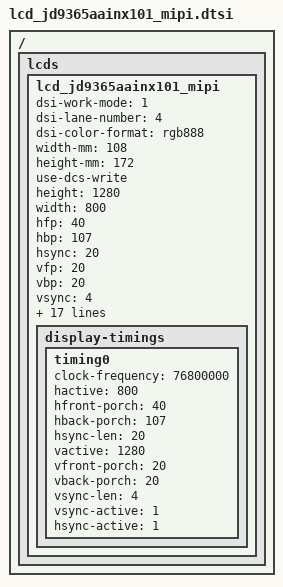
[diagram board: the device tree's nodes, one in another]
// SPDX-License-Identifier: GPL-2.0

/ { lcds: lcds {
        lcd_jd9365aainx101_mipi: lcd_jd9365aainx101_mipi {
                dsi-work-mode = <1>; /* video burst mode*/
                dsi-lane-number = <4>;
                dsi-color-format = "rgb888";
                width-mm = <108>;
                height-mm = <172>;
                use-dcs-write;

                /*mipi info*/
                height = <1280>;
                width = <800>;
                hfp = <40>;
                hbp = <107>;
                hsync = <20>;
                vfp = <20>;
                vbp = <20>;
                vsync = <4>;
                fps = <60>;
                work-mode = <0>;
                rgb-mode = <3>;
                lane-number = <4>;
                phy-bit-clock = <500000000>;
                split-enable = <0>;
                eotp-enable = <0>;
                burst-mode = <2>;
                esd-check-enable = <1>;

                /* DSI_CMD, DSI_MODE, timeout, len, cmd */
                initial-command = [
                        39 01 00 02 E0 00
                        39 01 00 02 E1 93
                        39 01 00 02 E2 65
                        39 01 00 02 E3 F8
                        39 01 00 02 80 03
                        39 01 00 02 E0 01
                        39 01 00 02 00 00
                        39 01 00 02 01 3B
                        39 01 00 02 0C 74
                        39 01 00 02 17 00
                        39 01 00 02 18 AF
                        39 01 00 02 19 00
                        39 01 00 02 1A 00
                        39 01 00 02 1B AF
                        39 01 00 02 1C 00
                        39 01 00 02 35 26
                        39 01 00 02 37 09
                        39 01 00 02 38 04
                        39 01 00 02 39 00
                        39 01 00 02 3A 01
                        39 01 00 02 3C 78
                        39 01 00 02 3D FF
                        39 01 00 02 3E FF
                        39 01 00 02 3F 7F
                        39 01 00 02 40 06
                        39 01 00 02 41 A0
                        39 01 00 02 42 81
                        39 01 00 02 43 14
                        39 01 00 02 44 23
                        39 01 00 02 45 28
                        39 01 00 02 55 02
                        39 01 00 02 57 69
                        39 01 00 02 59 0A
                        39 01 00 02 5A 2A
                        39 01 00 02 5B 17
                        39 01 00 02 5D 7F
                        39 01 00 02 5E 69
                        39 01 00 02 5F 59
                        39 01 00 02 60 4C
                        39 01 00 02 61 47
                        39 01 00 02 62 39
                        39 01 00 02 63 3B
                        39 01 00 02 64 24
                        39 01 00 02 65 3D
                        39 01 00 02 66 3C
                        39 01 00 02 67 3C
                        39 01 00 02 68 5A
                        39 01 00 02 69 46
                        39 01 00 02 6A 4A
                        39 01 00 02 6B 43
                        39 01 00 02 6C 46
                        39 01 00 02 6D 20
                        39 01 00 02 6E 0F
                        39 01 00 02 6F 00
                        39 01 00 02 70 7F
                        39 01 00 02 71 69
                        39 01 00 02 72 59
                        39 01 00 02 73 4C
                        39 01 00 02 74 47
                        39 01 00 02 75 39
                        39 01 00 02 76 3B
                        39 01 00 02 77 24
                        39 01 00 02 78 3D
                        39 01 00 02 79 3C
                        39 01 00 02 7A 3C
                        39 01 00 02 7B 5A
                        39 01 00 02 7C 46
                        39 01 00 02 7D 4A
                        39 01 00 02 7E 43
                        39 01 00 02 7F 46
                        39 01 00 02 80 20
                        39 01 00 02 81 0F
                        39 01 00 02 82 00
                        39 01 00 02 E0 02
                        39 01 00 02 00 42
                        39 01 00 02 01 42
                        39 01 00 02 02 40
                        39 01 00 02 03 40
                        39 01 00 02 04 5E
                        39 01 00 02 05 5E
                        39 01 00 02 06 5F
                        39 01 00 02 07 5F
                        39 01 00 02 08 5F
                        39 01 00 02 09 57
                        39 01 00 02 0A 57
                        39 01 00 02 0B 77
                        39 01 00 02 0C 77
                        39 01 00 02 0D 47
                        39 01 00 02 0E 47
                        39 01 00 02 0F 45
                        39 01 00 02 10 45
                        39 01 00 02 11 4B
                        39 01 00 02 12 4B
                        39 01 00 02 13 49
                        39 01 00 02 14 49
                        39 01 00 02 15 5F
                        39 01 00 02 16 41
                        39 01 00 02 17 41
                        39 01 00 02 18 40
                        39 01 00 02 19 40
                        39 01 00 02 1A 5E
                        39 01 00 02 1B 5E
                        39 01 00 02 1C 5F
                        39 01 00 02 1D 5F
                        39 01 00 02 1E 5F
                        39 01 00 02 1F 57
                        39 01 00 02 20 57
                        39 01 00 02 21 77
                        39 01 00 02 22 77
                        39 01 00 02 23 46
                        39 01 00 02 24 46
                        39 01 00 02 25 44
                        39 01 00 02 26 44
                        39 01 00 02 27 4A
                        39 01 00 02 28 4A
                        39 01 00 02 29 48
                        39 01 00 02 2A 48
                        39 01 00 02 2B 5F
                        39 01 00 02 2C 01
                        39 01 00 02 2D 01
                        39 01 00 02 2E 00
                        39 01 00 02 2F 00
                        39 01 00 02 30 1F
                        39 01 00 02 31 1F
                        39 01 00 02 32 1E
                        39 01 00 02 33 1E
                        39 01 00 02 34 1F
                        39 01 00 02 35 17
                        39 01 00 02 36 17
                        39 01 00 02 37 37
                        39 01 00 02 38 37
                        39 01 00 02 39 08
                        39 01 00 02 3A 08
                        39 01 00 02 3B 0A
                        39 01 00 02 3C 0A
                        39 01 00 02 3D 04
                        39 01 00 02 3E 04
                        39 01 00 02 3F 06
                        39 01 00 02 40 06
                        39 01 00 02 41 1F
                        39 01 00 02 42 02
                        39 01 00 02 43 02
                        39 01 00 02 44 00
                        39 01 00 02 45 00
                        39 01 00 02 46 1F
                        39 01 00 02 47 1F
                        39 01 00 02 48 1E
                        39 01 00 02 49 1E
                        39 01 00 02 4A 1F
                        39 01 00 02 4B 17
                        39 01 00 02 4C 17
                        39 01 00 02 4D 37
                        39 01 00 02 4E 37
                        39 01 00 02 4F 09
                        39 01 00 02 50 09
                        39 01 00 02 51 0B
                        39 01 00 02 52 0B
                        39 01 00 02 53 05
                        39 01 00 02 54 05
                        39 01 00 02 55 07
                        39 01 00 02 56 07
                        39 01 00 02 57 1F
                        39 01 00 02 58 40
                        39 01 00 02 5B 30
                        39 01 00 02 5C 16
                        39 01 00 02 5D 34
                        39 01 00 02 5E 05
                        39 01 00 02 5F 02
                        39 01 00 02 63 00
                        39 01 00 02 64 6A
                        39 01 00 02 67 73
                        39 01 00 02 68 1D
                        39 01 00 02 69 08
                        39 01 00 02 6A 6A
                        39 01 00 02 6B 08
                        39 01 00 02 6C 00
                        39 01 00 02 6D 00
                        39 01 00 02 6E 00
                        39 01 00 02 6F 88
                        39 01 00 02 75 FF
                        39 01 00 02 77 DD
                        39 01 00 02 78 3F
                        39 01 00 02 79 15
                        39 01 00 02 7A 17
                        39 01 00 02 7D 14
                        39 01 00 02 7E 82
                        39 01 00 02 E0 04
                        39 01 00 02 00 0E
                        39 01 00 02 02 B3
                        39 01 00 02 09 61
                        39 01 00 02 0E 48
                        39 01 00 02 E0 00
                        39 01 00 02 E6 02
                        39 01 00 02 E7 0C
                        39 01 78 02 11 00
                        39 01 00 02 E0 00
                        39 01 05 02 29 00
                        39 01 00 02 35 00
                ];

                sleep-in-command = [
                        39 01 78 01 28
                        39 01 78 01 10
                ];
                sleep-out-command = [
                        39 01 96 01 11
                        39 01 32 01 29
                ];
                read-id-command = [
                        37 01 00 01 01
                        14 01 00 01 04
                ];

                display-timings {
                        timing0 {
                                clock-frequency = <76800000>;
                                hactive = <800>;
                                hfront-porch = <40>;
                                hback-porch = <107>;
                                hsync-len = <20>;
                                vactive = <1280>;
                                vfront-porch = <20>;
                                vback-porch = <20>;
                                vsync-len = <4>;
                                vsync-active = <1>;
                                hsync-active = <1>;
                        };
                };
        };
};};
